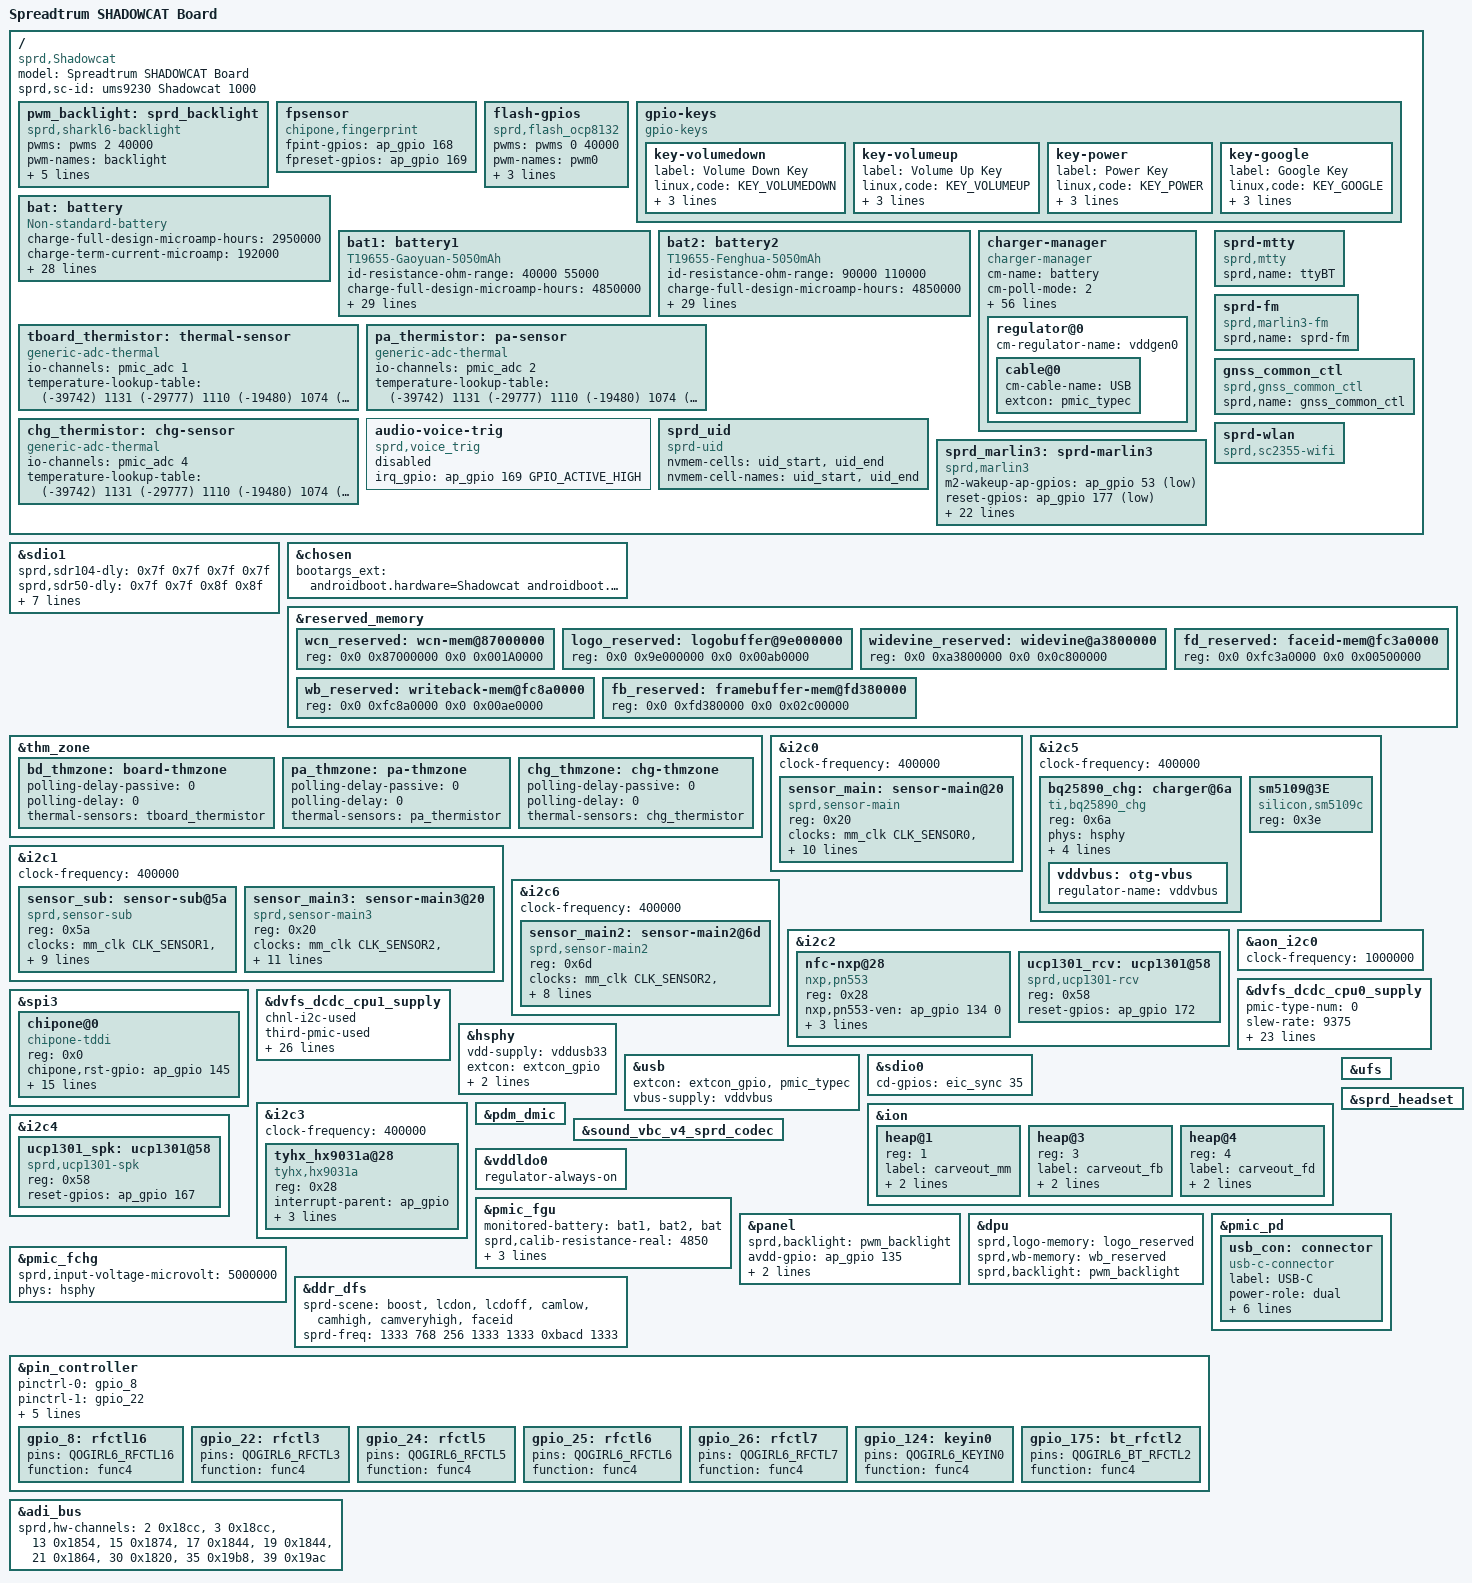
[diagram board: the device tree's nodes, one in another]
/dts-v1/;
/plugin/;
#include <dt-bindings/input/input.h>
#include <dt-bindings/gpio/gpio.h>
#include <dt-bindings/clock/sprd,ums9230-clk.h>
#include <dt-bindings/mfd/sprd,sc2730-regs.h>
#include <dt-bindings/mfd/sprd,sc2730-mask.h>
#include <dt-bindings/usb/pd.h>
//Modify by pengzhenhua1@wingtech.com for SCT-702 BSP bringup lcd on(2021.8.24) begin
//#include "lcd/lcd_g40396_truly_mipi_fhd.dtsi"
#include "lcd/lcd_icnl9911_skyworth_mipi_hdp.dtsi"
#include "lcd/lcd_icnl9911_skyworth_mantix_mipi_hdp.dtsi"  //Modify by pengzhenhua1@wingtech.com for OA4605210 BSP bringup lcd on(2021.11.10)
//Modify by pengzhenhua1@wingtech.com for SCT-702 BSP bringup lcd on(2021.8.24) end

#include "lcd/lcd_dummy_mipi.dtsi"

/ {

	model = "Spreadtrum SHADOWCAT Board";

	compatible = "sprd,Shadowcat";

	sprd,sc-id = "ums9230 Shadowcat 1000";
	fragment {
		target-path = "/";
		__overlay__ {
			pwm_backlight: sprd_backlight {
				compatible = "sprd,sharkl6-backlight";
				pwms = <&pwms 2 40000>;
				pwm-names = "backlight";
				sprd,max-brightness-level = <1023>;	//Modify by pengzhenhua1@wingtech.com for SCT-702,wt backlight to 50mA bringup on(2021.9.17)
				//zhiqing.liu modify, modify the default backlight brightness value, 2021.11.17 begin
				default-brightness-level = <847>; 	//Modify by pengzhenhua1@wingtech.com for SCT-702,wt backlight to 50mA bringup on(2021.9.17)
				//zhiqing.liu modify, modify the default backlight brightness value, 2021.11.17 end
				sprd,brightness-scale = <1023>;		//Modify by pengzhenhua1@wingtech.com for SCT-702,wt backlight to 50mA bringup on(2021.9.17)
//Modify by pengzhenhua1@wingtech.com for SCT-941,wt backlight 255level to 50mA 225level to 44mA bringup on(2021.10.21) begin
				brightness-levels = <
							  0   3   3   4   4   4 
					  5   5   5   5   5   6   6   6   6   7 
					  7   7   7   7   8   8   9   9  10  12 
					 13  13  14  14  15  15  16  17  17  18 
					 19  20  21  22  23  24  25  26  28  29 
					 30  31  33  34  36  37  38  40  41  43 
					 44  46  48  49  51  53  55  57  59  61 
					 62  64  66  68  70  72  74  76  78  80 
					 82  85  87  89  91  94  97  99 101 104 
					107 109 112 114 117 120 123 126 129 132 
					134 137 140 143 146 150 153 156 159 163 
					166 169 172 176 180 183 186 189 193 197 
					201 204 208 212 216 220 224 228 232 236 
					240 244 248 253 257 262 266 270 274 279 
					283 287 292 297 302 307 312 317 322 327 
					332 337 342 346 351 356 361 366 372 378 
					383 388 393 399 405 411 417 423 429 435 
					441 446 452 458 464 470 476 484 490 496 
					502 508 514 521 528 535 542 549 555 562 
					569 576 583 590 597 604 611 618 626 634 
					642 650 657 665 672 679 686 694 702 710 
					718 727 736 744 752 760 769 778 786 794 
					802 811 820 829 838 847 854 860 866 872 
					877 882 887 892 897 902 907 912 917 922
					927 932 937 942 947 952 957 962 967 972
					977 982 987 992 997 1002 1007 1012 1017 1023
				>;
//Modify by pengzhenhua1@wingtech.com for SCT-941,wt backlight 255level to 50mA 225level to 44mA bringup on(2021.10.21) end
			};
// Modify by liaomingzhe@wingtech.com for SCT-702 BSP bringup fingerprint on 2021-08-24 begin
			fpsensor {
				compatible = "chipone,fingerprint";
				fpint-gpios = <&ap_gpio 168 0 >;
				fpreset-gpios = <&ap_gpio 169 0 >;
			};
// Modify by liaomingzhe@wingtech.com for SCT-702 BSP bringup fingerprint on 2021-08-24 end

//Added by shaozhuchao@wingtech.com for SCT-702 flashic ocp8132 bringup on 2021-08-25 begin
			flash-gpios {
				compatible = "sprd,flash_ocp8132";
				//Modify by wangliang7@wingtech.com for SCT-702 flash modify from gpio to pwm 2021-11-24 Begin
				pwms = <&pwms 0 40000>;
				pwm-names = "pwm0";
				//Modify by wangliang7@wingtech.com for SCT-702 flash modify from gpio to pwm 2021-11-24 End
				flash-ic = <8132>;
				flash-torch-en-gpios = <&ap_gpio 139 0>;
				flash-en-gpios = <&ap_gpio 32 0>;
			};
//Added by shaozhuchao@wingtech.com for SCT-702 flashic ocp8132 bringup on 2021-08-25 end

			gpio-keys {
				compatible = "gpio-keys";

				key-volumedown {
					label = "Volume Down Key";
					linux,code = <KEY_VOLUMEDOWN>;
					gpios = <&ap_gpio 126 GPIO_ACTIVE_LOW>;/*Modify by wt.liuzhiqing for SCT-702, volumedown used gpio126*/
					debounce-interval = <2>;
					wakeup-source;
				};

				key-volumeup {
					label = "Volume Up Key";
					linux,code = <KEY_VOLUMEUP>;
					gpios = <&pmic_eic 4 GPIO_ACTIVE_HIGH>;
					debounce-interval = <2>;
					wakeup-source;
				};

				key-power {
					label = "Power Key";
					linux,code = <KEY_POWER>;
					gpios = <&pmic_eic 1 GPIO_ACTIVE_LOW>;
					debounce-interval = <2>;
					wakeup-source;
				};
				/*Add by wt.liuzhiqing for SCT-702,google key used gpio121 begin*/
				key-google {
					label = "Google Key";
					linux,code = <KEY_GOOGLE>;	 /* modify by wt.liuzhiqing for SCT-597,modify google key value: 752 */
					gpios = <&ap_gpio 121 GPIO_ACTIVE_LOW>;
					debounce-interval = <2>;
					wakeup-source;
				};
				/*Add by wt.liuzhiqing for SCT-702,google key used gpio121 end*/
			};
			/*Add by wt.liuzhiqing for SCT-702,modify charging parameters begin*/
/*+SCT-702, fangduozhu.wt, modify, 20210916, battery bringup*/
			bat: battery {
				compatible = "Non-standard-battery";
				charge-full-design-microamp-hours = <2950000>;
				charge-term-current-microamp = <192000>;
				constant_charge_voltage_max_microvolt = <4200000>;
				factory-internal-resistance-micro-ohms = <252000>;
				voltage-min-design-microvolt = <3450000>;
				charge-pumps-threshold-microvolt = <3400000>;
				ocv-capacity-celsius = <25>;
				ocv-capacity-table-0 = <4154000 100>, <4130000 95>, <4101000 90>,
							<4051000 85>, <4002000 80>, <3960000 75>,
							<3906000 70>, <3873000 65>, <3830000 60>,
							<3782000 55>, <3751000 50>, <3729000 45>,
							<3710000 40>, <3695000 35>, <3681000 30>,
							<3665000 25>, <3646000 20>, <3622000 15>,
							<3594000 10>, <3582000 5>, <3400000 0>;
				voltage-temp-table = <1095466 800>, <986112 850>, <878559 900>,
							  <775113 950>, <678461 1000>, <590240 1050>,
							  <510773 1100>, <440156 1150>, <378279 1200>,
							  <324561 1250>, <278079 1300>, <238260 1350>,
							  <204267 1400>, <175208 1450>, <150460 1500>,
							  <129410 1550>, <111497 1600>, <96484 1650>;
				capacity-temp-table = <45 100>, <25 100>, <10 100>, <0 95>, <(-10) 90>;
				resistance-temp-table = <45 53>, <25 100>, <10 395>, <0 567>, <(-10) 793>;
				charge-sdp-current-microamp = <500000 500000>;
				charge-dcp-current-microamp = <500000 500000>;
				charge-cdp-current-microamp = <500000 500000>;
				charge-unknown-current-microamp = <500000 500000>;
				charge-fchg-current-microamp = <500000 500000>;
				/*charge-flash-current-microamp = <5000000 2700000>;
				charge-wl-bpp-current-microamp = <1000000 1000000>;
				charge-wl-epp-current-microamp = <2000000 1000000>;*/
			};

			bat1: battery1 {
				compatible = "T19655-Gaoyuan-5050mAh";
				/*this is real id resistance, but accuracy of adc and material is not good*/
				/*id-resistance-ohm-range = <45590 48410>; typical-47000*/
				/*fixed id resistance(adc measured value)*/
				id-resistance-ohm-range = <40000 55000>;
				charge-full-design-microamp-hours = <4850000>;
				charge-term-current-microamp = <192000>;
				constant_charge_voltage_max_microvolt = <4384000>;
				factory-internal-resistance-micro-ohms = <117000>;
				voltage-min-design-microvolt = <3400000>;
				charge-pumps-threshold-microvolt = <42000000>;
				ocv-capacity-celsius = <25>;
				ocv-capacity-table-0 = <4358000 100>, <4316000 95>, <4258000 90>,
							<4201000 85>, <4145000 80>, <4092000 75>,
							<4050000 70>, <3985000 65>, <3952000 60>,
							<3894000 55>, <3857000 50>, <3830000 45>,
							<3809000 40>, <3792000 35>, <3777000 30>,
							<3757000 25>, <3738000 20>, <3714000 15>,
							<3685000 10>, <3672000 5>, <3400000 0>;
				/*modify by wt.liuzhiqing for SCT-702,modify battery NTC parameters begin*/
				voltage-temp-table = <1095466 800>, <986112 850>, <878559 900>,
							  <775113 950>, <678461 1000>, <590240 1050>,
							  <510773 1100>, <440156 1150>, <378279 1200>,
							  <324561 1250>, <278079 1300>, <238260 1350>,
							  <204267 1400>, <175208 1450>, <150460 1500>,
							  <129410 1550>, <111497 1600>, <96484 1650>;
				/*modify by wt.liuzhiqing for SCT-702,modify battery NTC parameters end*/
				capacity-temp-table = <50 98>, <25 100>, <10 99>, <0 97>, <(-10) 94>;
				resistance-temp-table = <50 90>, <25 100>, <10 145>, <0 550>, <(-10) 930>;
				charge-sdp-current-microamp = <500000 500000>;
				charge-dcp-current-microamp = <2500000 2200000>;
				charge-cdp-current-microamp = <1000000 1000000>;
				charge-unknown-current-microamp = <500000 500000>;
				charge-fchg-current-microamp = <3500000 2200000>;
				/*charge-flash-current-microamp = <5000000 2700000>;
				charge-wl-bpp-current-microamp = <1000000 1000000>;
				charge-wl-epp-current-microamp = <2000000 1000000>;*/
			};

			bat2: battery2 {
				compatible = "T19655-Fenghua-5050mAh";
				/*this is real id resistance, but accuracy of adc and material is not good*/
				/*id-resistance-ohm-range = <98000 102000>; typical-100000*/
				/*fixed id resistance(adc measured value)*/
				id-resistance-ohm-range = <90000 110000>;
				charge-full-design-microamp-hours = <4850000>;
				charge-term-current-microamp = <192000>;
				constant_charge_voltage_max_microvolt = <4384000>;
				factory-internal-resistance-micro-ohms = <130000>;
				voltage-min-design-microvolt = <3400000>;
				charge-pumps-threshold-microvolt = <42000000>;
				ocv-capacity-celsius = <25>;
				ocv-capacity-table-0 = <4355000 100>, <4310000 95>, <4251000 90>,
							<4193000 85>, <4137000 80>, <4084000 75>,
							<4038000 70>, <3981000 65>, <3943000 60>,
							<3886000 55>, <3850000 50>, <3825000 45>,
							<3805000 40>, <3789000 35>, <3774000 30>,
							<3756000 25>, <3738000 20>, <3713000 15>,
							<3685000 10>, <3670000 5>, <3400000 0>;
				voltage-temp-table = <1095466 800>, <986112 850>, <878559 900>,
							  <775113 950>, <678461 1000>, <590240 1050>,
							  <510773 1100>, <440156 1150>, <378279 1200>,
							  <324561 1250>, <278079 1300>, <238260 1350>,
							  <204267 1400>, <175208 1450>, <150460 1500>,
							  <129410 1550>, <111497 1600>, <96484 1650>;
				capacity-temp-table = <50 99>, <25 100>, <10 98>, <0 92>, <(-10) 71>;
				resistance-temp-table = <50 83>, <25 100>, <10 207>, <0 931>, <(-10) 1092>;
				charge-sdp-current-microamp = <500000 500000>;
				charge-dcp-current-microamp = <2500000 2200000>;
				charge-cdp-current-microamp = <1000000 1000000>;
				charge-unknown-current-microamp = <500000 500000>;
				charge-fchg-current-microamp = <3500000 2200000>;
				/*charge-flash-current-microamp = <5000000 2700000>;
				charge-wl-bpp-current-microamp = <1000000 1000000>;
				charge-wl-epp-current-microamp = <2000000 1000000>;*/
			};
/*-SCT-702, fangduozhu.wt, modify, 20210916, battery bringup*/
			charger-manager {
				compatible = "charger-manager";
				cm-name = "battery";
				cm-poll-mode = <2>;
				cm-poll-interval = <15000>;
				cm-battery-stat = <2>;

				cm-fullbatt-vchkdrop-ms = <30000>;
				cm-fullbatt-vchkdrop-volt = <100000>;
/*+SCT-702, fangduozhu.wt, modify, 20210923, let status can be full*/
				cm-fullbatt-voltage = <4384000>;
				cm-fullbatt-current = <200000>;
/*-SCT-702, fangduozhu.wt, modify, 20210923, let status can be full*/
				cm-fullbatt-capacity = <100>;
				/*Charge pump target charge current*/
				/*cm-cp-taper-current = <1000000>;*/

				cm-num-chargers = <1>;
				cm-num-charge-pumps = <1>;
				cm-num-fast-chargers = <1>;
				/*cm-num-wireless-chargers = <1>;
				cm-num-wireless-charge-pump-converters = <1>;
				*/
				cm-chargers = "bq25890_charger";
				/*cm-charge-pumps = "bq2597x-standalone";*/
				cm-fast-chargers = "sc2730_fast_charger";/*modify by wt.liuzhiqing for SCT-702,open fastcharge sc2730 */
				/*cm-wireless-chargers = "nu1619_wireless_charger";
				cm-wireless-charge-pump-converters = "hl1506_cp_converter";
				*/
				cm-fuel-gauge = "sc27xx-fgu";

				/* in deci centigrade */
				cm-battery-cold = <000>;
				cm-battery-cold-in-minus;
				cm-battery-hot = <550>;
				cm-battery-temp-diff = <30>;

				/* Allow charging for 8hr */
				cm-charging-max = <43200000>;
				/* recovery charging after stop charging 45min */
				cm-discharging-max = <2700000>;

				/* the interval to feed charger watchdog */
				cm-wdt-interval = <60>;

				/* drop voltage in microVolts to allow shutdown */
				cm-shutdown-voltage = <3100000>;

				/* when 99% of the time is exceeded, it will be forced to 100% */
				cm-tickle-time-out = <1500>;

				/* how much time to allow capacity change */
				cm-one-cap-time = <30>;
				cm-thermal-zone = "board-thmzone";
				/* when the safe charging voltage is exceeded, stop charging *//*9V 2A*/
				cm-charge-voltage-max = <6500000>;
				cm-fast-charge-voltage-max = <10500000>;
				/*cm-flash-charge-voltage-max = <10000000>;*/
				/*cm-wireless-charge-voltage-max = <6500000>;
				cm-wireless-fast-charge-voltage-max = <12000000>;*/
				/* drop voltage in microVolts to restart charging */
				cm-charge-voltage-drop = <700000>;
				cm-fast-charge-voltage-drop = <700000>;
				/*cm-flash-charge-voltage-drop = <1000000>;*/
				/*cm-wireless-charge-voltage-drop = <700000>;
				cm-wireless-fast-charge-voltage-drop = <1000000>;*/

				cm-dcp-jeita-temp-table = <1000 1030 0 4384000>, <1150 1180 800000 4384000>,
					<1450 1420 2500000 4384000>, <1550 1520 800000 4100000>;
				cm-sdp-jeita-temp-table = <1000 1030 0 4384000>, <1150 1180 500000 4384000>,
					<1450 1420 500000 4384000>, <1550 1520 500000 4100000>;
				cm-cdp-jeita-temp-table = <1000 1030 0 4384000>, <1150 1180 800000 4384000>,
					<1450 1420 1500000 4384000>, <1550 1520 800000 4100000>;
				cm-unknown-jeita-temp-table = <1000 1030 0 4384000>, <1150 1180 500000 4384000>,
					<1450 1420 500000 4384000>, <1550 1520 500000 4100000>;
				cm-fchg-jeita-temp-table = <1000 1030 0 4384000>, <1150 1180 800000 4384000>,
					<1450 1420 3500000 4384000>, <1600 1570 800000 4100000>;
				/*cm-flash-jeita-temp-table = <1000 1030 0 4384000>, <1150 1180 1000000 4384000>,
					<1450 1420 5000000 4384000>, <1600 1570 1000000 4100000>;
				cm-wl-bpp-jeita-temp-table = <1000 1030 0 4384000>, <1150 1180 500000 4384000>,
					<1450 1420 1000000 4384000>, <1600 1570 5000000 4100000>;
				cm-wl-epp-jeita-temp-table = <1000 1030 0 4384000>, <1150 1180 500000 4384000>,
					<1450 1420 2000000 4384000>, <1600 1570 500000 4100000>;
				*/
				cm-cap-remap-table = <1 2 3>, <2 3 2>, <98 99 2>, <99 100 3>;

/*SCT-702, fangduozhu.wt, modify, 20210916, battery bringup*/
				monitored-battery = <&bat1 &bat2 &bat>;
				cm-capacity-track;

				cm-ir-cv-offset-microvolt = <100000>;
				cm-ir-rc = <20>;
				cm-ir-us-upper-limit-microvolt = <4500000>;

				regulator@0 {
					cm-regulator-name = "vddgen0";
					cable@0 {
						cm-cable-name = "USB";
						extcon = <&pmic_typec>;
					};
				};
			};
			/*Add by wt.liuzhiqing for SCT-702,modify charging parameters end*/
			tboard_thermistor: thermal-sensor {
				compatible = "generic-adc-thermal";
				#thermal-sensor-cells = <0>;
				io-channels = <&pmic_adc 1>;
				io-channel-names = "sensor-channel";
				temperature-lookup-table = <
					(-39742) 1131
					(-29777) 1110
					(-19480) 1074
					(-4679) 983
					10110 838
					24805 654
					44922 413
					54903 316
					64895 238
					74884 178
					84883 133
					94883 100
					104880 75
					114889 57
					124872 43 >;
			};

			pa_thermistor: pa-sensor {
				compatible = "generic-adc-thermal";
				#thermal-sensor-cells = <0>;
				io-channels = <&pmic_adc 2>;
				io-channel-names = "sensor-channel";
				temperature-lookup-table = <
					(-39742) 1131
					(-29777) 1110
					(-19480) 1074
					(-4679) 983
					10110 838
					24805 654
					44922 413
					54903 316
					64895 238
					74884 178
					84883 133
					94883 100
					104880 75
					114889 57
					124872 43 >;
			};

			chg_thermistor: chg-sensor {
				compatible = "generic-adc-thermal";
				#thermal-sensor-cells = <0>;
				io-channels = <&pmic_adc 4>;
				io-channel-names = "sensor-channel";
				temperature-lookup-table = <
					(-39742) 1131
					(-29777) 1110
					(-19480) 1074
					(-4679) 983
					10110 838
					24805 654
					44922 413
					54903 316
					64895 238
					74884 178
					84883 133
					94883 100
					104880 75
					114889 57
					124872 43 >;
			};

			audio-voice-trig {
				status = "disable";
				compatible = "sprd,voice_trig";
				irq_gpio = <&ap_gpio 169 GPIO_ACTIVE_HIGH>;
			};

			sprd_uid {
				compatible = "sprd-uid";
				nvmem-cells = <&uid_start>, <&uid_end>;
				nvmem-cell-names = "uid_start", "uid_end";
			};

			sprd_marlin3: sprd-marlin3 {
				compatible = "sprd,marlin3";
				m2-wakeup-ap-gpios = <&ap_gpio 53 GPIO_ACTIVE_LOW>;
				reset-gpios = <&ap_gpio 177 GPIO_ACTIVE_LOW>;
				enable-gpios = <&ap_gpio 116 GPIO_ACTIVE_LOW>;
				m2-to-ap-irq-gpios = <&ap_gpio 52 GPIO_ACTIVE_LOW>;
				avdd12-supply = <&vddwcn>;
				avdd33-supply = <&vddwifipa>;
				dcxo18-supply = <&vddsim2>;

				clock-names = "clk_32k","source","enable";
				clocks = <&aon_clk CLK_AUX2>,
					 <&ext_32k>,
					 <&aonapb_gate CLK_AUX2_EB>;

				reg = <0 0x87000000 0 0x00100000>,
					<0 0x87100000 0 0xA0000>;
				reg-names = "btwf_mem", "gnss_mem";

				sdhci-name = <&sdio1>;
				sprd,btwf-file-name = "/dev/block/by-name/wcnmodem";
				sprd,gnss-file-name = "/dev/block/by-name/gnssmodem";
				adma-tx;
				adma-rx;

				/*
				 * bound parameter:
				 * [0]:addr offset, [1]:mask, [2]:unboundval, [3]:boundval
				 */
				avdd12-parent-bound-chip = <REG_ANA_SLP_DCDC_PD_CTRL MASK_ANA_SLP_DCDCGEN1_PD_EN 0x0 MASK_ANA_SLP_DCDCGEN1_PD_EN>;
				avdd12-bound-wbreq = <REG_ANA_LDO_XTL_EN10 MASK_ANA_LDO_VDDWCN_EXT_XTL3_EN 0x0 MASK_ANA_LDO_VDDWCN_EXT_XTL3_EN>;
				avdd33-bound-wbreq = <REG_ANA_LDO_XTL_EN11 MASK_ANA_LDO_VDDWIFIPA_EXT_XTL3_EN 0x0 MASK_ANA_LDO_VDDWIFIPA_EXT_XTL3_EN>;
			};

			sprd-mtty {
				compatible = "sprd,mtty";
				sprd,name = "ttyBT";
			};

			sprd-fm {
				compatible = "sprd,marlin3-fm";
				sprd,name = "sprd-fm";
			};

			gnss_common_ctl {
				compatible = "sprd,gnss_common_ctl";
				sprd,name = "gnss_common_ctl";
			};

			sprd-wlan{
				compatible = "sprd,sc2355-wifi";
			};
		};
	};
};

&sdio1 {
	sprd,sdr104-dly = <0x7f 0x7f 0x7f 0x7f>;
	sprd,sdr50-dly = <0x7f 0x7f 0x8f 0x8f>;
	sd-uhs-sdr104;
	sd-uhs-sdr50;
	bus-width = <4>;
	sprd,name = "sdio_wifi";
	sprd,sdio-adma;
	no-sd;
	no-mmc;
	status = "okay";
};

&chosen {
	bootargs_ext = "androidboot.hardware=Shadowcat androidboot.dtbo_idx=0";
};

&reserved_memory {
	wcn_reserved: wcn-mem@87000000 {
		reg = <0x0 0x87000000 0x0 0x001A0000>;
	};

	logo_reserved: logobuffer@9e000000{
		reg = <0x0 0x9e000000 0x0 0x00ab0000>;
	};

	widevine_reserved: widevine@a3800000 {
		reg = <0x0 0xa3800000 0x0 0x0c800000>;
	};

	fd_reserved: faceid-mem@fc3a0000 {
		reg = <0x0 0xfc3a0000 0x0 0x00500000>;
	};

	wb_reserved: writeback-mem@fc8a0000 {
		reg = <0x0 0xfc8a0000 0x0 0x00ae0000>;
	};

	fb_reserved: framebuffer-mem@fd380000 {
		reg = <0x0 0xfd380000 0x0 0x02c00000>;
	};
};

&thm_zone {
	bd_thmzone: board-thmzone {
		polling-delay-passive = <0>;
		polling-delay = <0>;
		thermal-sensors = <&tboard_thermistor>;
	};

	pa_thmzone: pa-thmzone {
		polling-delay-passive = <0>;
		polling-delay = <0>;
		thermal-sensors = <&pa_thermistor>;
	};

	chg_thmzone: chg-thmzone {
		polling-delay-passive = <0>;
		polling-delay = <0>;
		thermal-sensors = <&chg_thermistor>;
	};
};

&i2c0 {
	status = "okay";
	clock-frequency = <400000>;

	sensor_main: sensor-main@20 {
		compatible = "sprd,sensor-main";
		reg = <0x20>;
		clock-names = "clk_src","sensor_eb",
			"clk_96m","clk_76m8",
			"clk_48m","clk_26m";
		clocks = <&mm_clk CLK_SENSOR0>,<&mm_gate CLK_MM_SENSOR0_EB>,
				<&pll1 CLK_TWPLL_96M>,<&pll1 CLK_TWPLL_76M8>,
				<&pll1 CLK_TWPLL_48M>,<&ext_26m>;
		vddio-supply = <&vddcamio>;
		vddcama-supply = <&vddcama0>;
		dvdd-gpios = <&ap_gpio 137 0>;
		vddcammot-supply = <&vddcammot>;
		reset-gpios = <&ap_gpio 45 0>;
//Modify by chenhaidong@wingtech.com for SCT-702 Camera bringup on(2021.8.24) begin
		//power-down-gpios = <&ap_gpio 47 0>;
//Modify by chenhaidong@wingtech.com for SCT-702 Camera bringup on(2021.8.24) end
		sprd,phyid = <0>;
		csi = <&csi0>;
	};

};

&i2c1 {
	status = "okay";
	clock-frequency = <400000>;
//Modify by guozhiyong@wingtech.com for SCT-702 Camera bringup on(2021.8.24) begin
	sensor_sub: sensor-sub@5a {
		compatible = "sprd,sensor-sub";
		reg = <0x5a>;
		clock-names = "clk_src","sensor_eb",
			"clk_96m","clk_76m8",
			"clk_48m","clk_26m";
		clocks = <&mm_clk CLK_SENSOR1>,<&mm_gate CLK_MM_SENSOR1_EB>,
				<&pll1 CLK_TWPLL_96M>,<&pll1 CLK_TWPLL_76M8>,
				<&pll1 CLK_TWPLL_48M>,<&ext_26m>;
		vddio-supply = <&vddcamio>;
		vddcama-supply = <&vddcama1>;
		vddcamd-supply = <&vddcamd0>;
		reset-gpios = <&ap_gpio 44 0>;
		sprd,phyid = <2>;
		csi = <&csi1>;
	};

//Modify by guozhiyong@wingtech.com for SCT-702 Camera bringup on(2021.8.24) end

//Modify by gaozhiye1@wingtech.com for SCT-702 Camera macro bring up on(2021.8.26) begin
	sensor_main3: sensor-main3@20 {
		compatible = "sprd,sensor-main3";
		reg = <0x20>;
		clock-names = "clk_src","sensor_eb",
			"clk_96m","clk_76m8",
			"clk_48m","clk_26m";
		clocks = <&mm_clk CLK_SENSOR2>,<&mm_gate CLK_MM_SENSOR2_EB>,
				<&pll1 CLK_TWPLL_96M>,<&pll1 CLK_TWPLL_76M8>,
				<&pll1 CLK_TWPLL_48M>,<&ext_26m>;
		vddio-supply = <&vddcamio>;
		vddcama-supply = <&vddcama1>;
		vddcamd-supply = <&vddcamd0>;
		vddcammot-supply = <&vddcammot>;
		mot-gpios = <&ap_gpio 113 0>;
	//	reset-gpios = <&ap_gpio 41 0>;
		power-down-gpios = <&ap_gpio 47 0>;
	//	mipi-switch-en-gpios = <&ap_gpio 74 0>;
	//	mipi-switch-mode-gpios = <&ap_gpio 75 0>;
		sprd,phyid = <4>;
		csi = <&csi2>;
	};
//Modify by gaozhiye1@wingtech.com for SCT-702 Camera macro bring up on(2021.8.26) end

};

//Modify by wangliang7@wingtech.com for SCT-702 Camera bringup on(2021.8.25) begin
/*
&i2c1 {
	status = "okay";
	clock-frequency = <400000>;

	sensor_main3: sensor-main3@20 {
		compatible = "sprd,sensor-main3";
		reg = <0x20>;
		clock-names = "clk_src","sensor_eb",
			"clk_96m","clk_76m8",
			"clk_48m","clk_26m";
		clocks = <&mm_clk CLK_SENSOR1>,<&mm_gate CLK_MM_SENSOR1_EB>,
				<&pll1 CLK_TWPLL_96M>,<&pll1 CLK_TWPLL_76M8>,
				<&pll1 CLK_TWPLL_48M>,<&ext_26m>;
		vddio-supply = <&vddcamio>;
		vddcama-supply = <&vddcama1>;
		vddcamd-supply = <&vddcamd0>;
		vddcammot-supply = <&vddcammot>;
		mot-gpios = <&ap_gpio 113 0>;
		reset-gpios = <&ap_gpio 41 0>;
		power-down-gpios = <&ap_gpio 40 0>;
	//	mipi-switch-en-gpios = <&ap_gpio 55 0>;
	//	mipi-switch-mode-gpios = <&ap_gpio 8 0>;
		sprd,phyid = <4>;
		csi = <&csi1>;
	};
};
*/
//Modify by wangliang7@wingtech.com for SCT-702 Camera bringup on(2021.8.25) end

&i2c5 {
	status = "okay";
	clock-frequency = <400000>;
/*Add by wt.liuzhiqing for SCT-702,modify charging parameters , used charger ic bq25890 begin*/
/*
	bq2560x_chg: charger@6b {
		compatible = "ti,bq2560x_chg";
		reg = <0x6b>;
		phys = <&hsphy>;
		monitored-battery = <&bat1 &bat2 &bat>;
		extcon = <&extcon_gpio>, <&pmic_pd>;
		pd-extcon-enable;
		irq-gpio = <&ap_gpio 115 GPIO_ACTIVE_LOW>;
		vddvbus:otg-vbus {
			regulator-name = "vddvbus";
		};
	};
*/
	bq25890_chg: charger@6a {
		compatible = "ti,bq25890_chg";
		reg = <0x6a>;
		phys = <&hsphy>;
/*SCT-702, fangduozhu.wt, modify, 20210916, battery bringup*/
		monitored-battery = <&bat1 &bat2 &bat>;
		extcon = <&extcon_gpio>, <&pmic_pd>;
		pd-extcon-enable;
		irq-gpio = <&ap_gpio 115 GPIO_ACTIVE_LOW>;
		vddvbus:otg-vbus {
			regulator-name = "vddvbus";
		};
	};

/*	bq2597x_chg: charger@65 {
		compatible = "ti,bq2597x-standalone";
		reg = <0x65>;
		irq-gpio = <&ap_gpio 126 GPIO_ACTIVE_LOW>;

		ti,bq2597x,bus-therm-disable = <1>;
		ti,bq2597x,regulation-disable = <1>;

		ti,bq2597x,bat-ovp-threshold = <4400>;
		ti,bq2597x,bat-ovp-alarm-threshold = <4340>;
		ti,bq2597x,bat-ocp-threshold = <5500>;
		ti,bq2597x,bat-ocp-alarm-threshold = <5000>;
		ti,bq2597x,bus-ovp-threshold = <11500>;
		ti,bq2597x,bus-ovp-alarm-threshold = <10500>;
		ti,bq2597x,bus-ocp-threshold = <3000>;
		ti,bq2597x,bus-ocp-alarm-threshold = <2700>;
		ti,bq2597x,bat-ucp-alarm-threshold = <1000>;
		ti,bq2597x,bat-therm-threshold = <0x15>;
		ti,bq2597x,bus-therm-threshold = <0x15>;
		ti,bq2597x,die-therm-threshold = <0xc8>;
		ti,bq2597x,ac-ovp-threshold = <11>;
		ti,bq2597x,sense-resistor-mohm = <5>;
		ti,bq2597x,adc-sample-bits = <13>;
		ti,bq2597x,ibat-regulation-threshold = <300>;
		ti,bq2597x,vbat-regulation-threshold = <100>;
		ti,bq2597x,vdrop-threshold = <400>;
		ti,bq2597x,vdrop-deglitch = <5000>;
		ti,bq2597x,ss-timeout = <100000>;
		ti,bq2597x,watchdog-timer = <30000>;
	};

	hl1506_cp_converter: charger@1b {
		compatible = "halo,hl1506_cp_converter";
		reg = <0x1b>;
		chg_pump_en_gpio = <&ap_gpio 147 GPIO_ACTIVE_HIGH>;
	};

	nu1619_rx: charger@61 {
		compatible = "nuvolta,wl_charger_nu1619";
		reg = <0x61>;
		phys = <&hsphy>;
		rx,irq_gpio = <&ap_gpio 146 GPIO_ACTIVE_LOW>;
		switch_chg_en_gpio = <&ap_gpio 171 GPIO_ACTIVE_HIGH>;
		switch_flag_en_gpio = <&ap_gpio 176 GPIO_ACTIVE_HIGH>;
	};
*/
//modify by shaozhuchao@wingtech.com for SCT-702 comment out no use flashic ocp8137 on 2021-08-30 begin
	/*flash_ic: flash-ic@63 {
		compatible = "sprd,flash-ocp8137";
		reg = <0x63>;
		sprd,flash-ic = <8137>;
		sprd,torch = <1>;
		sprd,preflash = <1>;
		sprd,highlight = <1>;
		sprd,torch-level = <128>;
		sprd,preflash-level = <128>;
		sprd,highlight-level = <128>;
		sprd,lvfm-enable = <1>;
		flash-torch-en-gpios = <&ap_gpio 32 0>;
		flash-chip-en-gpios = <&ap_gpio 138 0>;
		flash-en-gpios = <&ap_gpio 139 0>;
		flash-sync-gpios = <&ap_gpio 121 0>;
	};*/
//modify by shaozhuchao@wingtech.com for SCT-702 comment out no use flashic ocp8137 on 2021-08-30 end
//Modify by pengzhenhua1@wingtech.com for SCT-702,wt add lcm bias driver(2021.10.21) begin	
	sm5109@3E {
		compatible = "silicon,sm5109c";
		reg = <0x3e>;
	};
//Modify by pengzhenhua1@wingtech.com for SCT-702,wt add lcm bias driver(2021.10.21) end	
};
/*Add by wt.liuzhiqing for SCT-702,modify charging parameters , used charger ic bq25890 end*/

//Modify by wangliang7@wingtech.com for SCT-702 Camera bringup on(2021.8.25) begin
/*
&i2c6 {
	status = "okay";
	clock-frequency = <400000>;

	sensor_sub2: sensor-sub2@6e {
		compatible = "sprd,sensor-sub2";
		reg = <0x6e>;
		clock-names = "clk_src","sensor_eb",
			"clk_96m","clk_76m8",
			"clk_48m","clk_26m";
		clocks = <&mm_clk CLK_SENSOR2>,<&mm_gate CLK_MM_SENSOR2_EB>,
			<&pll1 CLK_TWPLL_96M>,<&pll1 CLK_TWPLL_76M8>,
			<&pll1 CLK_TWPLL_48M>,<&ext_26m>;
		vddio-supply = <&vddcamio>;
		avdd-gpios = <&ap_gpio 130 0>;
		vddcamd-supply = <&vddcamd1>;
		vddcammot-supply = <&vddcammot>;
		mot-gpios = <&ap_gpio 112 0>;
		reset-gpios = <&ap_gpio 114 0>;
		power-down-gpios = <&ap_gpio 40 0>;
		sprd,phyid = <3>;
		csi = <&csi2>;
	};
};
*/

&i2c6 {
	status = "okay";
	clock-frequency = <400000>;

	sensor_main2: sensor-main2@6d {
		compatible = "sprd,sensor-main2";
		reg = <0x6d>;
		clock-names = "clk_src","sensor_eb",
			"clk_96m","clk_76m8",
			"clk_48m","clk_26m";
		clocks = <&mm_clk CLK_SENSOR2>,<&mm_gate CLK_MM_SENSOR2_EB>,
			<&pll1 CLK_TWPLL_96M>,<&pll1 CLK_TWPLL_76M8>,
			<&pll1 CLK_TWPLL_48M>,<&ext_26m>;
		vddio-supply = <&vddcamio>;
		vddcama-supply = <&vddcama1>;
		power-down-gpios = <&ap_gpio 40 0>;
		sprd,phyid = <3>;
		csi = <&csi2>;
	};
};
//Modify by wangliang7@wingtech.com for SCT-702 Camera bringup on(2021.8.25) end

//Modify by yangguoqiang@wingtech.com for SCT-702 BSP modify nfc bringup 2021-08-31 Begin
&i2c2 {
        status = "okay";
        nfc-nxp@28 {
        compatible = "nxp,pn553";
        reg = <0x28>;
        nxp,pn553-ven = <&ap_gpio 134 0>;
        nxp,pn553-fw-dwnld = <&ap_gpio 16 0>;
        nxp,pn553-irq = <&ap_gpio 30 0>;
        nxp,pn553-clk-req = <&ap_gpio 15 0>;
        };
};
//Modify by yangguoqiang@wingtech.com for SCT-702 BSP modify nfc bringup 2021-08-31 End

&aon_i2c0 {
	status = "okay";
	clock-frequency = <1000000>;
};

&spi3 {
	status = "okay";
// Modify by fangzhihua@wingtech.com for SCT-702 BSP bringup TP on 2021-08-24 begin
	/*focaltech@0 {
		compatible = "focaltech,fts";
		reg = <0x0>;
		focaltech,reset-gpio = <&ap_gpio 145 GPIO_ACTIVE_HIGH>;
		focaltech,irq-gpio = <&ap_gpio 144 GPIO_ACTIVE_HIGH>;
		focaltech,max-touch-number = <5>;
		focaltech,display-coords =  <0 0 1080 2400>;
		spi-max-frequency = <6000000>;
	}; */
	chipone@0 {
		compatible = "chipone-tddi";
		reg = <0x0>;
		chipone,rst-gpio = <&ap_gpio 145 GPIO_ACTIVE_HIGH>;
		chipone,irq-gpio = <&ap_gpio 144 GPIO_ACTIVE_HIGH>;

		// Modify by fangzhihua@wingtech.com for SCT-702 BSP FAE modify and add charger and Earjack code on 2021-12-06 begin
		chipone,x-res = <719>;
		chipone,y-res = <1599>;
		spi-max-frequency = <6000000>;

		/* Charger detect */
		chipone,touch-charger-detect-enable;
		chipone,touch-charger-detect-type = "notify"; /* notify, poll */
		// Modify by fangzhihua@wingtech.com for wt bug 709887,710864 ghost point on 2021-12-28 begin
		chipone,touch-charger-detect-psy-name = "battery";
		chipone,touch-charger-detect-psp = "POWER_SUPPLY_PROP_ONLINE";
		chipone,touch-charger-detect-psp-poll-interval = <2000>;
		// Modify by fangzhihua@wingtech.com for wt bug 709887,710864 ghost point on 2021-12-28 end

		/* Earjack detect */
		chipone,touch-earjack-detect-enable;
		chipone,touch-earjack-state-filepath = "/sys/kernel/headset/state";
		chipone,touch-earjack-poll-interval = <1000>;
		// Modify by fangzhihua@wingtech.com for SCT-702 BSP FAE modify and add charger and Earjack code on 2021-12-06 end
	};
// Modify by fangzhihua@wingtech.com for SCT-702 BSP bringup TP on 2021-08-24 end
};

&dvfs_dcdc_cpu0_supply {
	pmic-type-num = <0>;
	slew-rate = <9375>; /* 9375uV/us */
	top-dvfs-adi-state = <0x70 0 0xf>;
	voltage-grade-num = <8>;
	voltage-grade = <0 0xf0 0xf4 0 0x1ff>,
		<1 0xf0 0xf4 9 0x1ff>,
		<2 0x100 0xf4 18 0x1ff>,
		<3 0x110 0xf8 0 0x1ff>,
		<4 0x120 0xf8 9 0x1ff>,
		<5 0x130 0xf8 18 0x1ff>,
		<6 0x140 0xfc 0 0x1ff>,
		<7 0x140 0xfc 9 0x1ff>;
	voltage-up-delay = <50 0x58 0 0xffff 0x600>,
		<100 0x58 16 0xffff 0xa00>,
		<150 0x54 0 0xffff 0xf00>,
		<200 0x54 16 0xffff 0x1400>,
		<250 0x50 0 0xffff 0x1900>,
		<300 0x50 16 0xffff 0x1e00>,
		<350 0x110 0 0xffff 0x2300>;
	voltage-down-delay = <50 0x64 0 0xffff 0x600>,
		<100 0x64 16 0xffff 0xa00>,
		<150 0x60 0 0xffff 0xf00>,
		<200 0x60 16 0xffff 0x1400>,
		<250 0x5c 0 0xffff 0x1900>,
		<300 0x5c 16 0xffff 0x1e00>,
		<350 0x114 0 0xffff 0x2300>;
	tuning-latency-us = <0>;
	chnl-in-i2c = <0>;
};

&dvfs_dcdc_cpu1_supply {
	chnl-i2c-used;
	third-pmic-used;
	pmic-type-num = <2>;
	slew-rate = <4000>; /* 4000uV/us */
	supply-type-sel = <0x120 0 1>;
	top-dvfs-i2c-state = <0x9c 4 0x1f>;
	voltage-grade-num = <8>;
/*Added by wt.yanrenjie for SCT-702,wt ETA355 force pwm begin*/
	voltage-grade = <0 0xcf 0x12c 0 0xff>,
		<1 0xd4 0x12c 8 0xff>,
		<2 0xd9 0x12c 16 0xff>,
		<3 0xde 0x12c 24 0xff>,
		<4 0xe3 0x130 0 0xff>,
		<5 0xe8 0x130 8 0xff>,
		<6 0xe8 0x130 16 0xff>,
		<7 0xe8 0x130 24 0xff>;
/*Added by wt.yanrenjie for SCT-702,wt ETA355 force pwm end*/
	voltage-up-delay = <50 0x84 0 0xffff 0x1600>,
		<100 0x84 16 0xffff 0x1a00>,
		<150 0x80 0 0xffff 0x1f00>,
		<200 0x80 16 0xffff 0x2400>,
		<250 0x7c 0 0xffff 0x2900>,
		<300 0x7c 16 0xffff 0x2e00>,
		<350 0x118 0 0xffff 0x3300>;
	voltage-down-delay = <50 0x90 0 0xffff 0x600>,
		<100 0x90 16 0xffff 0xa00>,
		<150 0x8c 0 0xffff 0xf00>,
		<200 0x8c 16 0xffff 0x1400>,
		<250 0x88 0 0xffff 0x1900>,
		<300 0x88 16 0xffff 0x1e00>,
		<350 0x11c 0 0xffff 0x2300>;
	tuning-latency-us = <0>;
	chnl-in-i2c = <1>;
};

&hsphy {
	vdd-supply = <&vddusb33>;
	extcon = <&extcon_gpio>;
	sprd,hsphy-device-eye-pattern = <0x04f3d1c0>;
	sprd,hsphy-host-eye-pattern = <0x04f3d1c0>;
	status = "okay";
};

&usb {
	extcon = <&extcon_gpio>, <&pmic_typec>;
	vbus-supply = <&vddvbus>;
	status = "okay";
};

&sdio0 {
	cd-gpios = <&eic_sync 35 GPIO_ACTIVE_HIGH>;
};

&ion {
	heap@1 {
		reg = <1>;
		label = "carveout_mm";
		type = <2>;
		memory-region = <&widevine_reserved>;
	};

	heap@3 {
		reg = <3>;
		label = "carveout_fb";
		type = <2>;
		memory-region = <&fb_reserved>;
	};
};

&ufs {
	status = "okay";
};

&i2c2 {
	status = "okay";
	ucp1301_rcv: ucp1301@58 {
		compatible = "sprd,ucp1301-rcv";
		reg = <0x58>;
		reset-gpios = <&ap_gpio 172 GPIO_ACTIVE_HIGH>;
		#sound-dai-cells = <1>;
	};
};
// added by chenweican@wingtech.com for SCT-702 BSP bringup sensor on 2021-08-24 begin
&i2c3 {
	status = "okay";
        clock-frequency = <400000>;
        tyhx_hx9031a@28 {
		compatible = "tyhx,hx9031a";
		reg = <0x28>;
		interrupt-parent = <&ap_gpio>;
		interrupts = <176 0>;
		tyhx,nirq-gpio = <&ap_gpio 176 0x00>;
		tyhx,channel-flag = <0x01>;
	};

};
// added by chenweican@wingtech.com for SCT-702 BSP bringup sensor on 2021-08-24 end

&i2c4 {
	status = "okay";
	ucp1301_spk: ucp1301@58 {
		compatible = "sprd,ucp1301-spk";
		reg = <0x58>;
		reset-gpios = <&ap_gpio 167 GPIO_ACTIVE_HIGH>;
		#sound-dai-cells = <1>;
	};
};

&sprd_headset {
	status = "okay";
        //Deleted by qiuyonghui.wt for audio bring up
};

&pdm_dmic {
	status = "okay";
};

&sound_vbc_v4_sprd_codec {
	status = "okay";
	//Deleted by qiuyonghui.wt for audio bring up




};

&vddldo0 {
	regulator-always-on;
};

&pmic_fgu {
/*SCT-702, fangduozhu.wt, modify, 20210916, battery bringup*/
	monitored-battery = <&bat1 &bat2 &bat>;
	sprd,calib-resistance-real = <4850>;
	sprd,calib-resistance-spec = <20000>;
	first-calib-voltage = <3580000>;
	first-calib-capacity = <50>;
};

&panel {
	sprd,backlight = <&pwm_backlight>;

	avdd-gpio = <&ap_gpio 135 GPIO_ACTIVE_HIGH>;
	avee-gpio = <&ap_gpio 136 GPIO_ACTIVE_HIGH>;
	reset-gpio = <&ap_gpio 50 GPIO_ACTIVE_HIGH>;
};

&dpu {
	sprd,logo-memory = <&logo_reserved>;
	sprd,wb-memory = <&wb_reserved>;

	sprd,backlight = <&pwm_backlight>;
//Modify by pengzhenhua1@wingtech.com for SCT-702 BSP bringup lcd on(2021.8.24) begin
//	sprd,dpi-clk-div = <6>;
//Modify by pengzhenhua1@wingtech.com for SCT-702 BSP bringup lcd on(2021.8.24) end
};
//Modify by pengzhenhua1@wingtech.com for SCT-702 BSP bringup lcd on(2021.8.24) begin
/*
&lcd_g40396_truly_mipi_fhd {
	display-timings {
		g40396_truly_timing1: timing1 {
			clock-frequency = <192000000>;
			hactive = <720>;
			vactive = <1600>;
			hback-porch = <75>;
			hfront-porch = <75>;
			vback-porch = <32>;
			vfront-porch = <8>;
			hsync-len = <75>;
			vsync-len = <8>;
		};
	};
};
*/
//Modify by pengzhenhua1@wingtech.com for SCT-702,wt dynamic frame rate adjustment bringup on(2021.9.7) begin
/*
&lcd_icnl9911_skyworth_mipi_hdp {
	display-timings {
		icnl9911_skyworth_timing1: timing1 {
			clock-frequency = <192000000>;
			hactive = <720>;
			vactive = <1600>;
			hback-porch = <75>;
			hfront-porch = <75>;
			vback-porch = <32>;
			vfront-porch = <8>;
			hsync-len = <75>;
			vsync-len = <8>;
		};
	};
};
*/
//Modify by pengzhenhua1@wingtech.com for SCT-702,wt dynamic frame rate adjustment bringup on(2021.9.7) end
//Modify by pengzhenhua1@wingtech.com for SCT-702 BSP bringup lcd on(2021.8.24) end

&pmic_fchg {
	sprd,input-voltage-microvolt = <5000000>;
	phys = <&hsphy>;
};

&pmic_pd {
	status = "okay";
	usb_con: connector {
		compatible = "usb-c-connector";
		label = "USB-C";
		power-role = "dual";
		try-power-role = "sink";
		source-pdos = <PDO_FIXED(5000, 400, PDO_FIXED_USB_COMM)>;
		sink-pdos = <PDO_FIXED(5000, 2000, PDO_FIXED_USB_COMM)
			     PDO_PPS_APDO(3300, 11000, 3000)>;
		op-sink-microwatt = <10000000>;
	};
};

&ddr_dfs {
	  sprd-scene = "boost", "lcdon", "lcdoff", "camlow",
			"camhigh", "camveryhigh", "faceid";
	  sprd-freq = <1333 768 256 1333 1333 0xbacd 1333>;
};

&pin_controller {
	pinctrl-names =
	/* rfctl16 ,rfctl3, rfctl5 */
	"gpio_8", "gpio_22", "gpio_24",
	/* rfctl6, rfctl7, keyin0 */
	"gpio_25", "gpio_26", "gpio_124",
	/* bt_rfctl2 */
	"gpio_175";
	pinctrl-0 = <&gpio_8>;
	pinctrl-1 = <&gpio_22>;
	pinctrl-2 = <&gpio_24>;
	pinctrl-3 = <&gpio_25>;
	pinctrl-4 = <&gpio_26>;
	pinctrl-5 = <&gpio_124>;
	pinctrl-6 = <&gpio_175>;

	gpio_8: rfctl16 {
		pins = "QOGIRL6_RFCTL16";
		function = "func4";
	};

	gpio_22: rfctl3 {
		pins = "QOGIRL6_RFCTL3";
		function = "func4";
	};

	gpio_24: rfctl5 {
		pins = "QOGIRL6_RFCTL5";
		function = "func4";
	};

	gpio_25: rfctl6 {
		pins = "QOGIRL6_RFCTL6";
		function = "func4";
	};

	gpio_26: rfctl7 {
		pins = "QOGIRL6_RFCTL7";
		function = "func4";
	};

	gpio_124: keyin0 {
		pins = "QOGIRL6_KEYIN0";
		function = "func4";
	};

	gpio_175: bt_rfctl2 {
		pins = "QOGIRL6_BT_RFCTL2";
		function = "func4";
	};
};

&ion {
	heap@4 {
		reg = <4>;
		label = "carveout_fd";
		type = <2>;
		memory-region = <&fd_reserved>;
	};
};

&adi_bus {
	sprd,hw-channels = <2 0x18cc>, <3 0x18cc>, <13 0x1854>, <15 0x1874>,
			<17 0x1844>,<19 0x1844>, <21 0x1864>, <30 0x1820>,
			<35 0x19b8>, <39 0x19ac>;
};
